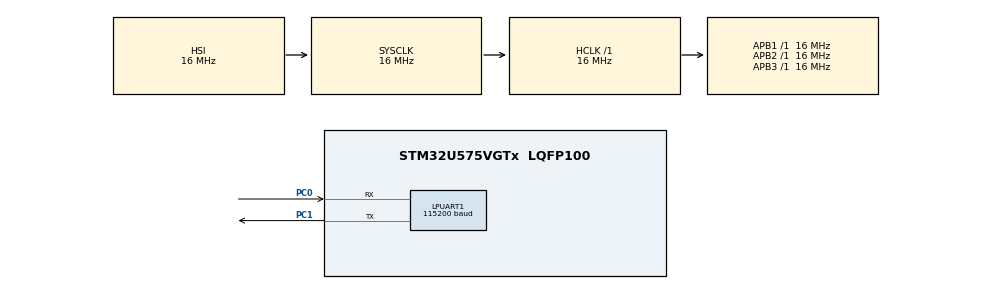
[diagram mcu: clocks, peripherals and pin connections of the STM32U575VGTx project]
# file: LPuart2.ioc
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CORTEX_M33_NS.userName=CORTEX_M33
LPUART1.BaudRate=115200
Mcu.Family=STM32U5
Mcu.Name=STM32U575VGTx
Mcu.Package=LQFP100
NVIC.LPUART1_IRQn=true\:0\:0\:false\:false\:true\:true\:true\:true
NVIC.PriorityGroup=NVIC_PRIORITYGROUP_4
PA13\ (JTMS/SWDIO).Mode=Serial_Wire
PA13\ (JTMS/SWDIO).Signal=DEBUG_JTMS-SWDIO
PA14\ (JTCK/SWCLK).Mode=Serial_Wire
PA14\ (JTCK/SWCLK).Signal=DEBUG_JTCK-SWCLK
PC0.Mode=Asynchronous
PC0.Signal=LPUART1_RX
PC1.Mode=Asynchronous
PC1.Signal=LPUART1_TX
ProjectManager.HeapSize=0x200
ProjectManager.StackSize=0x400
ProjectManager.TargetToolchain=MDK-ARM V5.39
RCC.ADCFreq_Value=16000000
RCC.AHBFreq_Value=16000000
RCC.APB1Freq_Value=16000000
RCC.APB1TimFreq_Value=16000000
RCC.APB2Freq_Value=16000000
RCC.APB2TimFreq_Value=16000000
RCC.APB3Freq_Value=16000000
RCC.CortexFreq_Value=16000000
RCC.EPOD_VALUE=4000000
RCC.HCLKFreq_Value=16000000
RCC.HSE_VALUE=16000000
RCC.HSI48_VALUE=48000000
RCC.HSI_VALUE=16000000
RCC.LSE_VALUE=32768
RCC.LSIDIV_VALUE=32000
RCC.MSI_VALUE=4000000
RCC.SYSCLKFreq_VALUE=16000000
RCC.SYSCLKSource=RCC_SYSCLKSOURCE_HSI
RCC.USBFreq_Value=48000000
RCC.VCOOutputFreq_Value=516000000
VP_LPBAMQUEUE_VS_QUEUE.Mode=QUEUEMODE
VP_LPBAM_VS_SIG1.Mode=SmartRun
VP_LPBAM_VS_SIG4.Mode=LPDMA1
VP_MEMORYMAP_VS_MEMORYMAP.Mode=CurAppReg
VP_PWR_VS_SECSignals.Mode=Security/Privilege
board=custom

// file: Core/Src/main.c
/* USER CODE BEGIN Header */
/**
  ******************************************************************************
  * @file           : main.c
  * @brief          : Main program body - Board 2: Receive + append '*' + send back
  ******************************************************************************
  */
/* USER CODE END Header */
#include "main.h"

/* USER CODE BEGIN Includes */
#include <string.h>
/* USER CODE END Includes */

/* USER CODE BEGIN PD */
#define BUF_SIZE        256
#define IDLE_TIMEOUT_MS 30     /* Frame ends after 30ms of silence */
/* USER CODE END PD */

UART_HandleTypeDef hlpuart1;

/* USER CODE BEGIN PV */
uint8_t  rx_buf[BUF_SIZE];
uint8_t  tx_buf[BUF_SIZE + 1];   /* +1 for '*' */
uint16_t rx_idx = 0;
uint32_t last_rx_tick = 0;
uint8_t  rx_active = 0;
/* USER CODE END PV */

void SystemClock_Config(void);
static void MX_GPIO_Init(void);
static void MX_LPUART1_UART_Init(void);

int main(void)
{

  /* MCU Configuration--------------------------------------------------------*/

  /* Reset of all peripherals, Initializes the Flash interface and the Systick. */
  HAL_Init();

  /* Configure the system clock */
  SystemClock_Config();

  /* Initialize all configured peripherals */
  MX_GPIO_Init();
  MX_LPUART1_UART_Init();
  /* USER CODE BEGIN 2 */

  /* Disable RXNE interrupt - we use polling in main loop */
  LPUART1->CR1 &= ~USART_CR1_RXNEIE_RXFNEIE;
  HAL_NVIC_DisableIRQ(LPUART1_IRQn);

  /* Clear any pending flags */
  LPUART1->ICR = 0xFFFFFFFF;

  /* Power-on banner */
  HAL_UART_Transmit(&hlpuart1, (uint8_t*)"[Board2] Ready\r\n", 16, 1000);

  /* USER CODE END 2 */

  /* Infinite loop */
  while (1)
  {

    /* USER CODE BEGIN 3 */

    /* Poll RX: if RDR has data, read it into frame buffer */
    if (LPUART1->ISR & USART_ISR_RXNE_RXFNE)
    {
      uint8_t data = (uint8_t)(LPUART1->RDR & 0xFF);

      if (rx_idx < BUF_SIZE)
      {
        rx_buf[rx_idx++] = data;
      }
      rx_active = 1;
      last_rx_tick = HAL_GetTick();
    }

    /* Clear any error flags to prevent lockup */
    if (LPUART1->ISR & (USART_ISR_ORE | USART_ISR_FE | USART_ISR_NE | USART_ISR_PE))
    {
      LPUART1->ICR = USART_ICR_ORECF | USART_ICR_FECF | USART_ICR_NECF | USART_ICR_PECF;
    }

    /* Check if a frame has ended (no new byte for IDLE_TIMEOUT_MS) */
    if (rx_active && (HAL_GetTick() - last_rx_tick >= IDLE_TIMEOUT_MS))
    {
      uint16_t len = rx_idx;
      rx_idx = 0;
      rx_active = 0;

      if (len > 0 && len <= BUF_SIZE)
      {
        /* Copy frame and append '*' */
        memcpy(tx_buf, rx_buf, len);
        tx_buf[len] = '*';

        /* Send back */
        HAL_UART_Transmit(&hlpuart1, tx_buf, len + 1, 100);
      }
    }

  }
  /* USER CODE END 3 */
}

void SystemClock_Config(void)
{
  RCC_OscInitTypeDef RCC_OscInitStruct = {0};
  RCC_ClkInitTypeDef RCC_ClkInitStruct = {0};

  /** Configure the main internal regulator output voltage
  */
  if (HAL_PWREx_ControlVoltageScaling(PWR_REGULATOR_VOLTAGE_SCALE4) != HAL_OK)
  {
    Error_Handler();
  }

  /** Initializes the CPU, AHB and APB buses clocks
  */
  RCC_OscInitStruct.OscillatorType = RCC_OSCILLATORTYPE_HSI;
  RCC_OscInitStruct.HSIState = RCC_HSI_ON;
  RCC_OscInitStruct.HSICalibrationValue = RCC_HSICALIBRATION_DEFAULT;
  RCC_OscInitStruct.PLL.PLLState = RCC_PLL_NONE;
  if (HAL_RCC_OscConfig(&RCC_OscInitStruct) != HAL_OK)
  {
    Error_Handler();
  }

  /** Initializes the CPU, AHB and APB buses clocks
  */
  RCC_ClkInitStruct.ClockType = RCC_CLOCKTYPE_HCLK|RCC_CLOCKTYPE_SYSCLK
                              |RCC_CLOCKTYPE_PCLK1|RCC_CLOCKTYPE_PCLK2
                              |RCC_CLOCKTYPE_PCLK3;
  RCC_ClkInitStruct.SYSCLKSource = RCC_SYSCLKSOURCE_HSI;
  RCC_ClkInitStruct.AHBCLKDivider = RCC_SYSCLK_DIV1;
  RCC_ClkInitStruct.APB1CLKDivider = RCC_HCLK_DIV1;
  RCC_ClkInitStruct.APB2CLKDivider = RCC_HCLK_DIV1;
  RCC_ClkInitStruct.APB3CLKDivider = RCC_HCLK_DIV1;

  if (HAL_RCC_ClockConfig(&RCC_ClkInitStruct, FLASH_LATENCY_1) != HAL_OK)
  {
    Error_Handler();
  }
}

static void MX_LPUART1_UART_Init(void)
{

  hlpuart1.Instance = LPUART1;
  hlpuart1.Init.BaudRate = 115200;
  hlpuart1.Init.WordLength = UART_WORDLENGTH_8B;
  hlpuart1.Init.StopBits = UART_STOPBITS_1;
  hlpuart1.Init.Parity = UART_PARITY_NONE;
  hlpuart1.Init.Mode = UART_MODE_TX_RX;
  hlpuart1.Init.HwFlowCtl = UART_HWCONTROL_NONE;
  hlpuart1.Init.OneBitSampling = UART_ONE_BIT_SAMPLE_DISABLE;
  hlpuart1.Init.ClockPrescaler = UART_PRESCALER_DIV1;
  hlpuart1.AdvancedInit.AdvFeatureInit = UART_ADVFEATURE_NO_INIT;
  hlpuart1.FifoMode = UART_FIFOMODE_DISABLE;
  if (HAL_UART_Init(&hlpuart1) != HAL_OK)
  {
    Error_Handler();
  }
  if (HAL_UARTEx_SetTxFifoThreshold(&hlpuart1, UART_TXFIFO_THRESHOLD_1_8) != HAL_OK)
  {
    Error_Handler();
  }
  if (HAL_UARTEx_SetRxFifoThreshold(&hlpuart1, UART_RXFIFO_THRESHOLD_1_8) != HAL_OK)
  {
    Error_Handler();
  }
  if (HAL_UARTEx_DisableFifoMode(&hlpuart1) != HAL_OK)
  {
    Error_Handler();
  }

}

static void MX_GPIO_Init(void)
{

  /* GPIO Ports Clock Enable */
  __HAL_RCC_GPIOC_CLK_ENABLE();
  __HAL_RCC_GPIOA_CLK_ENABLE();

}

void Error_Handler(void)
{
  __disable_irq();
  while (1)
  {
  }
}
